# APM32F445 register map
File version: 1.0
CPU: CM4 r0p1, little endian, MPU, FPU, 4 interrupt priority bits
Registers are 32-bit, read-write, reset 0x0 unless marked. A register's access mark holds for its fields unless they carry their own. Offsets are from the block's base; [hi:lo] are bit positions; 'fields as' and 'values as' point back to an identical list.

## RMU — Reset Management unit
Base 0x4007F000
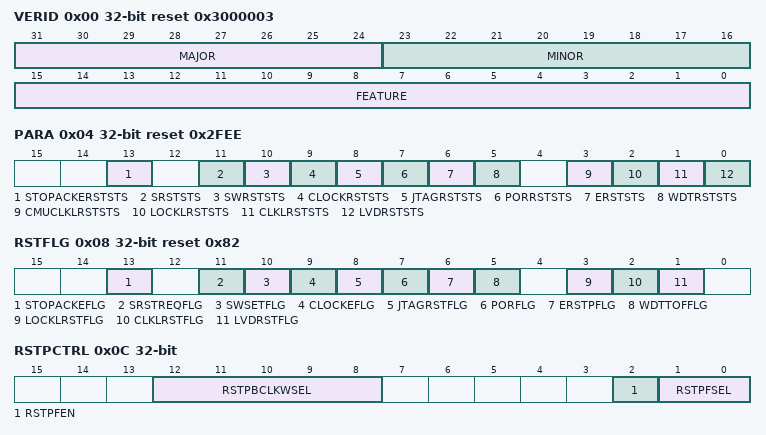
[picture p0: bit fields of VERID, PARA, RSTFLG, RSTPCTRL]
0x00 VERID ro reset 0x3000003 — Version ID Register
  [31:24] MAJOR — Major Version ID
  [23:16] MINOR — Minor Version ID
  [15:0] FEATURE — Feature ID
    3=Standard feature set
0x04 PARA ro reset 0x2FEE — Parameter Register
  [all] fields
    0=The feature is not available; 1=The feature is available
  [13] STOPACKERSTSTS — Stop Acknowledge Error Reset Function Status
  [11] SRSTSTS — System Reset Function Status
  [10] SWRSTSTS — Software Reset Function Status
  [9] CLOCKRSTSTS — Core Lockup Reset Function Status
  [8] JTAGRSTSTS — JTAG Reset Function Status
  [7] PORRSTSTS — POR Reset Function Status
  [6] ERSTSTS — External Pin Reset Function Status
  [5] WDTRSTSTS — Watchdog Timer Reset Function Status
  [3] CMUCLKLRSTSTS — CMU Clock Circuit Loss Reset Function Status
  [2] LOCKLRSTSTS — Lock Loss Reset Function Status
  [1] CLKLRSTSTS — Clock Loss Reset Function Status
  [0] LVDRSTSTS — Low Voltage Detection Reset Function Status
0x08 RSTFLG ro reset 0x82 — Reset Status Register
  [13] STOPACKEFLG — Stop Acknowledge Error Flag
    0=Reset not caused by peripheral failure to acknowledge attempt to enter stop mode; 1=Reset caused by peripheral failure to acknowledge attempt to enter stop mode
  [11] SRSTREQFLG — System Reset Request Flag
    0=Reset was not caused by host debugger system setting of the System Reset Request bit; 1=Reset was caused by host debugger system setting of the System Reset Request bit
  [10] SWSETFLG — Software Set Flag
    0=Reset not caused by software setting of SYSRESETREQ bit; 1=Reset caused by software setting of SYSRESETREQ bit
  [9] CLOCKEFLG — Core Lockup Event Flag
    0=Reset not caused by core LOCKUP event; 1=Reset caused by core LOCKUP event
  [8] JTAGRSTFLG — JTAG Reset Flag
    0=Reset not caused by JTAG; 1=Reset caused by JTAG
  [7] PORFLG — POR Flag
    0=Reset not caused by POR; 1=Reset caused by POR
  [6] ERSTPFLG — External Reset Pin Flag
    0=Reset not caused by external reset pin; 1=Reset caused by external reset pin
  [5] WDTTOFFLG — Watchdog Timer Timeout Flag
    0=Reset not caused by watchdog timeout; 1=Reset caused by watchdog timeout
  [3] LOCKLRSTFLG — Lock Loss Reset Flag
    0=Reset not caused by a loss of lock in the PLL/FLL; 1=Reset caused by a loss of lock in the PLL/FLL
  [2] CLKLRSTFLG — Clock Loss Reset Flag
    0=Reset not caused by a loss of external clock; 1=Reset caused by a loss of external clock
  [1] LVDRSTFLG — Low Voltage Detection Reset Flag
    0=Reset not caused by LVD trip, HVD trip or POR; 1=Reset caused by LVD trip, HVD trip or POR
0x0C RSTPCTRL — Reset Pin Control register
  [12:8] RSTPBCLKWSEL — Reset Pin Bus Clock Filter Width Select
  [2] RSTPFEN — Reset Pin Filter Enable in Stop Mode
    0=All filtering disabled; 1=LPO clock filter enabled
  [1:0] RSTPFSEL — Reset Pin Filter Select in Run and Wait Modes
    0=All filtering disabled; 1=Bus clock filter enabled for normal operation; 2=LPO clock filter enabled for normal operation
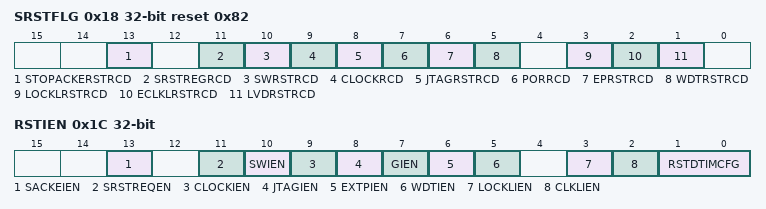
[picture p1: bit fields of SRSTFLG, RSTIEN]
0x18 SRSTFLG reset 0x82 — Sticky Reset Flag Register
  [13] STOPACKERSTRCD — Stop Acknowledge Error Reset Record
    values as RSTFLG.STOPACKEFLG
  [11] SRSTREGRCD — System Reset Request Record
    values as RSTFLG.SRSTREQFLG
  [10] SWRSTRCD — Software Reset Record
    values as RSTFLG.SWSETFLG
  [9] CLOCKRCD — Core Lockup Reset Record
    values as RSTFLG.CLOCKEFLG
  [8] JTAGRSTRCD — JTAG Reset Record
    0=Reset not caused by JTAG; 1=Reset caused by JTAG
  [7] PORRCD — Power-On Reset Record
    0=Reset not caused by POR; 1=Reset caused by POR
  [6] EPRSTRCD — External Pin Reset Record
    values as RSTFLG.ERSTPFLG
  [5] WDTRSTRCD — Watchdog Timer Reset Record
    values as RSTFLG.WDTTOFFLG
  [3] LOCKLRSTRCD — Lock Loss Reset Record
    values as RSTFLG.LOCKLRSTFLG
  [2] ECLKLRSTRCD — Clock Loss Reset Record
    values as RSTFLG.CLKLRSTFLG
  [1] LVDRSTRCD — LVD Reset Record
    0=Reset not caused by LVD trip or POR; 1=Reset caused by LVD trip or POR
0x1C RSTIEN — Reset Interrupt Enable Register
  [13] SACKEIEN — Stop Acknowledge Error Interrupt Enable
    0=Interrupt disabled; 1=Interrupt enabled
  [11] SRSTREQEN — System Reset Request Enable
    0=Interrupt disabled; 1=Interrupt enabled
  [10] SWIEN — Software Interrupt Enable
    0=Interrupt disabled; 1=Interrupt enabled
  [9] CLOCKIEN — Core Lockup Interrupt Enable
    0=Interrupt disabled; 1=Interrupt enabled
  [8] JTAGIEN — JTAG Interrupt Enable
    0=Interrupt disabled; 1=Interrupt enabled
  [7] GIEN — Global Interrupt Enable
    0=All interrupt sources disabled; 1=All interrupt sources enabled. Note that the individual interrupt-enable bits still need to be set to generate interrupts.
  [6] EXTPIEN — External Reset Pin Interrupt Enable
    values as RSTFLG.ERSTPFLG
  [5] WDTIEN — Watchdog Timer Interrupt Enable
    0=Interrupt disabled; 1=Interrupt enabled
  [3] LOCKLIEN — Lock Loss Interrupt Enable
    0=Interrupt disabled; 1=Interrupt enabled
  [2] CLKLIEN — Clock Loss Interrupt Enable
    0=Interrupt disabled; 1=Interrupt enabled
  [1:0] RSTDTIMCFG — Reset Delay Time Configure
    0=10 LPO cycles; 1=34 LPO cycles; 2=130 LPO cycles; 3=514 LPO cycles
